# STM32MP157 register map
File version: 1.6
CPU: CM4 r0p1, little endian, no MPU, FPU, 4 interrupt priority bits
Registers are 32-bit, read-write, reset 0x0 unless marked. A register's access mark holds for its fields unless they carry their own. Offsets are from the block's base; [hi:lo] are bit positions; {n}, {i} and the like mark numbered series.

## BSEC — BSEC2
Base 0x5C005000
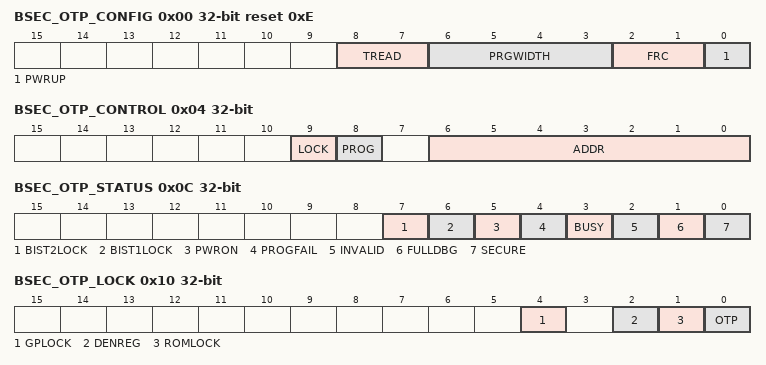
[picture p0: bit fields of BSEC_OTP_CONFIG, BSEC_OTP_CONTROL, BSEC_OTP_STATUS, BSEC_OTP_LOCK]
0x00 BSEC_OTP_CONFIG reset 0xE — BSEC OTP configuration register
  [8:7] TREAD, [6:3] PRGWIDTH, [2:1] FRC, [0] PWRUP
0x04 BSEC_OTP_CONTROL
  [9] LOCK, [8] PROG, [6:0] ADDR
0x08 BSEC_OTP_WRDATA — BSEC OTP write data register
0x0C BSEC_OTP_STATUS ro
  [7] BIST2LOCK, [6] BIST1LOCK, [5] PWRON, [4] PROGFAIL, [3] BUSY, [2] INVALID, [1] FULLDBG, [0] SECURE
0x10 BSEC_OTP_LOCK — BSEC OTP lock configuration register
  [4] GPLOCK, [2] DENREG, [1] ROMLOCK, [0] OTP
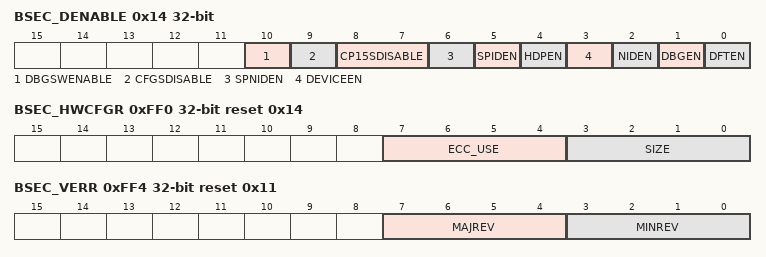
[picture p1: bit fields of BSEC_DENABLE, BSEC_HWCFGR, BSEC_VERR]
0x14 BSEC_DENABLE — reset value depends on OTP secure mode according toTable18: BSEC_DENABLE default values after reset on page181.
  [10] DBGSWENABLE, [9] CFGSDISABLE, [8:7] CP15SDISABLE, [6] SPNIDEN, [5] SPIDEN, [4] HDPEN, [3] DEVICEEN, [2] NIDEN, [1] DBGEN, [0] DFTEN
{0x1C+4i} BSEC_OTP_DISTURBED{i} ro (i=0..2) — BSEC_OTP_DISTURBED0 is used to report disturbed state of BSEC_OTP_DATA0 to BSEC_OTP_DATA31 (lower 1Kbits OTP). BSEC_OTP_DISTURBED1 is used to report disturbed state of BSEC_OTP_DATA32 to BSEC_OTP_DATA63. BSEC_OTP_DISTURBED2 is used to report disturbed state of BSEC_OTP_DATA64 to BSEC_OTP_DATA95.
  [31:0] DIS
{0x34+4i} BSEC_OTP_ERROR{i} ro (i=0..2) — BSEC_OTP_ERROR0 is used to report error state of BSEC_OTP_DATA0 to BSEC_OTP_DATA31 (lower 1Kbits OTP which are protected by 2:1 redundancy). BSEC_OTP_ERROR1 is used to report error state of BSEC_OTP_DATA32 to BSEC_OTP_DATA63 which are protected by 6-bit ECC. BSEC_OTP_ERROR2 is used to report error state of BSEC_OTP_DATA64 to BSEC_OTP_DATA95 which are protected by 6-bit ECC.
  [31:0] ERR
{0x4C+4i} BSEC_OTP_WRLOCK{i} ro (i=0..2) — BSEC_OTP_WLOCK0 is used to report permanent write lock of BSEC_OTP_DATA0 to BSEC_OTP_DATA31. BSEC_OTP_WLOCK1 is used to report permanent write lock of BSEC_OTP_DATA32 to BSEC_OTP_DATA63. BSEC_OTP_WLOCK2 is used to report permanent write lock of BSEC_OTP_DATA64 to BSEC_OTP_DATA95. Permanent write lock requires a programming sequence to lock a word (see section:Section3.3.6: OTP operations on page178).
  [31:0] WRLOCK
{0x64+4i} BSEC_OTP_SPLOCK{i} (i=0..2) — BSEC_OTP_SPLOCK0 is used to lock the programming of BSEC_OTP_DATA0 to BSEC_OTP_DATA31 until next system-reset BSEC_OTP_SPLOCK1 is used to lock the programming of BSEC_OTP_DATA32 to BSEC_OTP_DATA63 until next system-reset BSEC_OTP_SPLOCK2 is used to lock the programming of BSEC_OTP_DATA64 to BSEC_OTP_DATA95 until next system-reset Attempt to sticky program locked OTP word are silently ignored.
  [31:0] SPLOCK
{0x7C+4i} BSEC_OTP_SWLOCK{i} reset 0x1 (i=0..2) — BSEC_OTP_SWLOCK0 is used to prevent writing to BSEC_OTP_DATA0 to BSEC_OTP_DATA31 until next system-reset. BSEC_OTP_SWLOCK1 is used to prevent writing to BSEC_OTP_DATA32 to BSEC_OTP_DATA63 until next system-reset. BSEC_OTP_SWLOCK2 is used to prevent writing to BSEC_OTP_DATA64 to BSEC_OTP_DATA95 until next system-reset. Write to shadow write locked BSEC_OTP_DATA word are silently ignored. Writing to OTP word 0 shadow is always prevented.
  [31:0] SWLOCK
{0x94+4i} BSEC_OTP_SRLOCK{i} (i=0..2) — BSEC_OTP_SRLOCK0 is used to prevent reloading of BSEC_OTP_DATA0 to BSEC_OTP_DATA31 until next system-reset. BSEC_OTP_SRLOCK1 is used to prevent reloading of BSEC_OTP_DATA32 to BSEC_OTP_DATA63 until next system-reset. BSEC_OTP_SRLOCK2 is used to prevent reloading of BSEC_OTP_DATA64 to BSEC_OTP_DATA95 until next system-reset. Setting SRLOCK bits or attempt to reload a locked OTP do not clear the corresponding BSEC_OTP_DATAx shadow register. BSEC_OTP_SRLOCK0 bit 0 is controlled by hardware according to fuse_ok, writing to this bit has no effect.
  [31:0] SRLOCK
0xAC BSEC_JTAGIN ro — BSEC JTAG input register
  [15:0] DATA
0xB0 BSEC_JTAGOUT — BSEC JTAG output register
  [15:0] DATA
0xB4 BSEC_SCRATCH
  [31:0] DATA
{0x200+4i} BSEC_OTP_DATA{i} (i=0..95) — Several OTP directly impact BSEC behavior, such as: BSEC_OTP_DATA0[6:0] (see Table15: OTP modes definition on page175) BSEC_OTP_DATA1, 16 lsb used for SoC features control BSEC_OTP_DATA2, 2 lsb used to control the RAM handling The reset value depends on the actual OTP programmed value and the OTP mode.
  [31:0] DATA
0xFF0 BSEC_HWCFGR ro reset 0x14 — BSEC hardware configuration register
  [7:4] ECC_USE, [3:0] SIZE
0xFF4 BSEC_VERR ro reset 0x11 — BSEC version register
  [7:4] MAJREV, [3:0] MINREV
0xFF8 BSEC_IPIDR ro reset 0x100032 — BSEC identification register
  [31:0] ID
0xFFC BSEC_SIDR ro reset 0xA3C5DD04 — BSEC size identification register
  [31:0] SID
